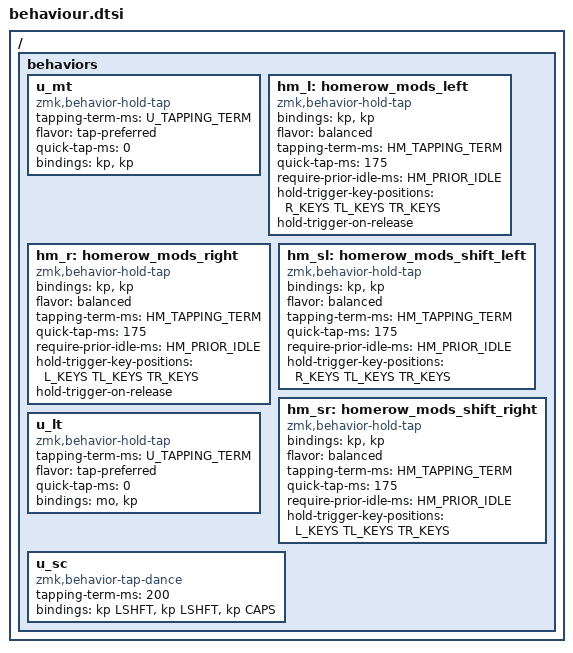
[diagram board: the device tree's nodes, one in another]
#define HM_TAPPING_TERM 300
#define HM_TAPPING_TERM_FAST 200
#define HM_PRIOR_IDLE 150

#define L_KEYS 0 1 2 3 4 10 11 12 13 14 20 21 22 23 24
#define R_KEYS 5 6 7 8 9 15 16 17 18 19 25 26 27 28 29
#define TL_KEYS 30 31
#define TR_KEYS 32 33

/ {
    behaviors {
        u_mt: u_mt {
            compatible = "zmk,behavior-hold-tap";
            #binding-cells = <2>;
            tapping-term-ms = <U_TAPPING_TERM>;
            flavor = "tap-preferred";
            quick-tap-ms = <0>;
            bindings = <&kp>, <&kp>;
        };

        hm_l: homerow_mods_left {
            compatible = "zmk,behavior-hold-tap";
            #binding-cells = <2>;
            bindings = <&kp>,  <&kp>;

            flavor = "balanced";
            tapping-term-ms = <HM_TAPPING_TERM>;
            quick-tap-ms = <175>;                // repeat on tap-into-hold
            require-prior-idle-ms = <HM_PRIOR_IDLE>;

            hold-trigger-key-positions = <R_KEYS TL_KEYS TR_KEYS>;
            hold-trigger-on-release;
        };

        hm_r: homerow_mods_right {
            compatible = "zmk,behavior-hold-tap";
            #binding-cells = <2>;
            bindings = <&kp>, <&kp>;

            flavor = "balanced";
            tapping-term-ms = <HM_TAPPING_TERM>;
            quick-tap-ms = <175>;
            require-prior-idle-ms = <HM_PRIOR_IDLE>;

            hold-trigger-key-positions = <L_KEYS TL_KEYS TR_KEYS>;
            hold-trigger-on-release;
        };

        hm_sl: homerow_mods_shift_left {
            compatible = "zmk,behavior-hold-tap";
            #binding-cells = <2>;
            bindings = <&kp>,  <&kp>;

            flavor = "balanced";
            tapping-term-ms = <HM_TAPPING_TERM>;
            quick-tap-ms = <175>;                // repeat on tap-into-hold
            require-prior-idle-ms = <HM_PRIOR_IDLE>;

            hold-trigger-key-positions = <R_KEYS TL_KEYS TR_KEYS>;
        };

        hm_sr: homerow_mods_shift_right {
            compatible = "zmk,behavior-hold-tap";
            #binding-cells = <2>;
            bindings = <&kp>, <&kp>;

            flavor = "balanced";
            tapping-term-ms = <HM_TAPPING_TERM>;
            quick-tap-ms = <175>;
            require-prior-idle-ms = <HM_PRIOR_IDLE>;

            hold-trigger-key-positions = <L_KEYS TL_KEYS TR_KEYS>;
        };

        u_lt: u_lt {
            compatible = "zmk,behavior-hold-tap";
            #binding-cells = <2>;
            tapping-term-ms = <U_TAPPING_TERM>;
            flavor = "tap-preferred";
            quick-tap-ms = <0>;
            bindings = <&mo>, <&kp>;
        };

        // Hold: LSHFT
        // CAPS is activated by tapping shift key trice
        u_sc: u_sc {
            compatible = "zmk,behavior-tap-dance";
            #binding-cells = <0>;
            tapping-term-ms = <200>;
            bindings = <&kp LSHFT>, <&kp LSHFT>, <&kp CAPS>;
        };
  };
};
